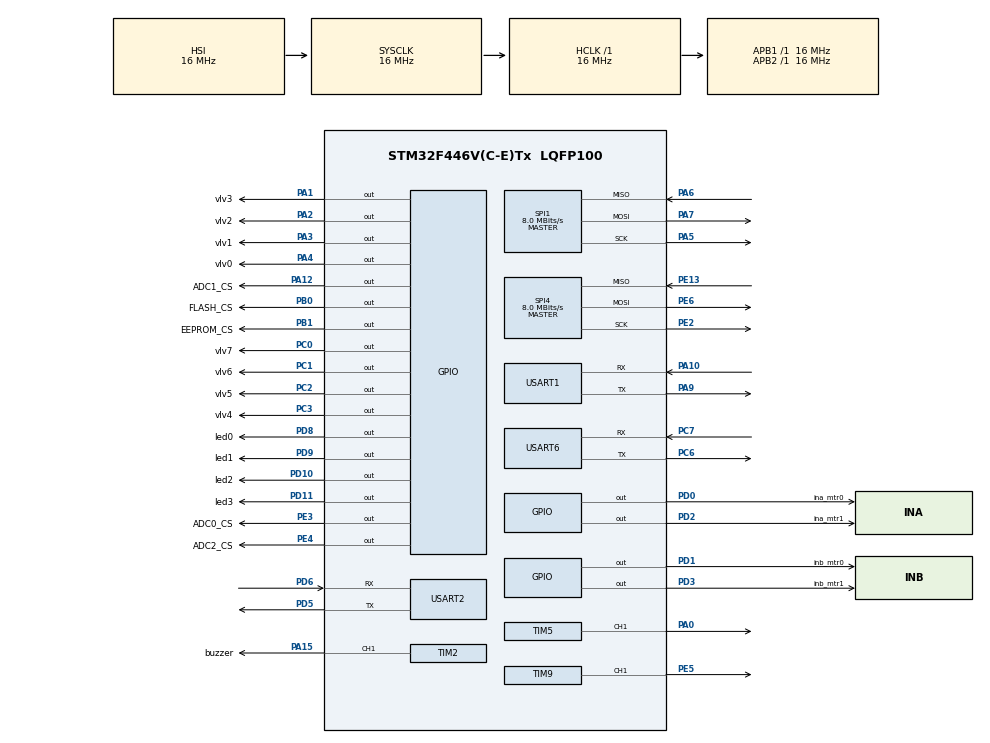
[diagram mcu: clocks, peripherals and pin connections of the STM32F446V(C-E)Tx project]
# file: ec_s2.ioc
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Mcu.Family=STM32F4
Mcu.Name=STM32F446V(C-E)Tx
Mcu.Package=LQFP100
NVIC.PriorityGroup=NVIC_PRIORITYGROUP_4
PA0-WKUP.Signal=S_TIM5_CH1
PA1.GPIO_Label=vlv3
PA1.Signal=GPIO_Output
PA10.Mode=Asynchronous
PA10.Signal=USART1_RX
PA12.GPIO_Label=ADC1_CS
PA12.Signal=GPIO_Output
PA13.Mode=Trace_Asynchronous_SW
PA13.Signal=SYS_JTMS-SWDIO
PA14.Mode=Trace_Asynchronous_SW
PA14.Signal=SYS_JTCK-SWCLK
PA15.GPIO_Label=buzzer
PA15.Signal=S_TIM2_CH1_ETR
PA2.GPIO_Label=vlv2
PA2.Signal=GPIO_Output
PA3.GPIO_Label=vlv1
PA3.Signal=GPIO_Output
PA4.GPIO_Label=vlv0
PA4.Signal=GPIO_Output
PA5.Mode=Full_Duplex_Master
PA5.Signal=SPI1_SCK
PA6.Mode=Full_Duplex_Master
PA6.Signal=SPI1_MISO
PA7.Mode=Full_Duplex_Master
PA7.Signal=SPI1_MOSI
PA9.Mode=Asynchronous
PA9.Signal=USART1_TX
PB0.GPIO_Label=FLASH_CS
PB0.Signal=GPIO_Output
PB1.GPIO_Label=EEPROM_CS
PB1.Signal=GPIO_Output
PB3.Mode=Trace_Asynchronous_SW
PB3.Signal=SYS_JTDO-SWO
PC0.GPIO_Label=vlv7
PC0.Signal=GPIO_Output
PC1.GPIO_Label=vlv6
PC1.Signal=GPIO_Output
PC2.GPIO_Label=vlv5
PC2.Signal=GPIO_Output
PC3.GPIO_Label=vlv4
PC3.Signal=GPIO_Output
PC6.Mode=Asynchronous
PC6.Signal=USART6_TX
PC7.Mode=Asynchronous
PC7.Signal=USART6_RX
PD0.GPIO_Label=ina_mtr0
PD0.Signal=GPIO_Output
PD1.GPIO_Label=inb_mtr0
PD1.Signal=GPIO_Output
PD10.GPIO_Label=led2
PD10.Signal=GPIO_Output
PD11.GPIO_Label=led3
PD11.Signal=GPIO_Output
PD2.GPIO_Label=ina_mtr1
PD2.Signal=GPIO_Output
PD3.GPIO_Label=inb_mtr1
PD3.Signal=GPIO_Output
PD5.Mode=Asynchronous
PD5.Signal=USART2_TX
PD6.Mode=Asynchronous
PD6.Signal=USART2_RX
PD8.GPIO_Label=led0
PD8.Signal=GPIO_Output
PD9.GPIO_Label=led1
PD9.Signal=GPIO_Output
PE13.Mode=Full_Duplex_Master
PE13.Signal=SPI4_MISO
PE2.Mode=Full_Duplex_Master
PE2.Signal=SPI4_SCK
PE3.GPIO_Label=ADC0_CS
PE3.Signal=GPIO_Output
PE4.GPIO_Label=ADC2_CS
PE4.Signal=GPIO_Output
PE5.Signal=S_TIM9_CH1
PE6.Mode=Full_Duplex_Master
PE6.Signal=SPI4_MOSI
ProjectManager.HeapSize=0x200
ProjectManager.StackSize=0x400
ProjectManager.TargetToolchain=TrueSTUDIO
RCC.AHBFreq_Value=16000000
RCC.APB1Freq_Value=16000000
RCC.APB1TimFreq_Value=16000000
RCC.APB2Freq_Value=16000000
RCC.APB2TimFreq_Value=16000000
RCC.CortexFreq_Value=16000000
RCC.HCLKFreq_Value=16000000
RCC.SYSCLKFreq_VALUE=16000000
RCC.USBFreq_Value=96000000
RCC.VCOOutputFreq_Value=192000000
SH.S_TIM2_CH1_ETR.0=TIM2_CH1,PWM Generation1 CH1
SH.S_TIM5_CH1.0=TIM5_CH1,PWM Generation1 CH1
SH.S_TIM9_CH1.0=TIM9_CH1,PWM Generation1 CH1
SPI1.BaudRatePrescaler=SPI_BAUDRATEPRESCALER_2
SPI1.CalculateBaudRate=8.0 MBits/s
SPI1.Direction=SPI_DIRECTION_2LINES
SPI1.Mode=SPI_MODE_MASTER
SPI1.VirtualType=VM_MASTER
SPI4.BaudRatePrescaler=SPI_BAUDRATEPRESCALER_2
SPI4.CalculateBaudRate=8.0 MBits/s
SPI4.Direction=SPI_DIRECTION_2LINES
SPI4.Mode=SPI_MODE_MASTER
SPI4.VirtualType=VM_MASTER
TIM2.Channel-PWM\ Generation1\ CH1=TIM_CHANNEL_1
TIM5.Channel-PWM\ Generation1\ CH1=TIM_CHANNEL_1
TIM9.Channel-PWM\ Generation1\ CH1=TIM_CHANNEL_1
USART1.VirtualMode=VM_ASYNC
USART2.VirtualMode=VM_ASYNC
USART6.VirtualMode=VM_ASYNC
board=ec_s2

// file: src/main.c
/**
  ******************************************************************************
  * @file           : main.c
  * @brief          : Main program body
  ******************************************************************************
  ** This notice applies to any and all portions of this file
  * that are not between comment pairs USER CODE BEGIN and
  * USER CODE END. Other portions of this file, whether
  * inserted by the user or by software development tools
  * are owned by their respective copyright owners.
  *
  * COPYRIGHT(c) 2018 STMicroelectronics
  *
  * Redistribution and use in source and binary forms, with or without modification,
  * are permitted provided that the following conditions are met:
  *   1. Redistributions of source code must retain the above copyright notice,
  *      this list of conditions and the following disclaimer.
  *   2. Redistributions in binary form must reproduce the above copyright notice,
  *      this list of conditions and the following disclaimer in the documentation
  *      and/or other materials provided with the distribution.
  *   3. Neither the name of STMicroelectronics nor the names of its contributors
  *      may be used to endorse or promote products derived from this software
  *      without specific prior written permission.
  *
  * THIS SOFTWARE IS PROVIDED BY THE COPYRIGHT HOLDERS AND CONTRIBUTORS "AS IS"
  * AND ANY EXPRESS OR IMPLIED WARRANTIES, INCLUDING, BUT NOT LIMITED TO, THE
  * IMPLIED WARRANTIES OF MERCHANTABILITY AND FITNESS FOR A PARTICULAR PURPOSE ARE
  * DISCLAIMED. IN NO EVENT SHALL THE COPYRIGHT HOLDER OR CONTRIBUTORS BE LIABLE
  * FOR ANY DIRECT, INDIRECT, INCIDENTAL, SPECIAL, EXEMPLARY, OR CONSEQUENTIAL
  * DAMAGES (INCLUDING, BUT NOT LIMITED TO, PROCUREMENT OF SUBSTITUTE GOODS OR
  * SERVICES; LOSS OF USE, DATA, OR PROFITS; OR BUSINESS INTERRUPTION) HOWEVER
  * CAUSED AND ON ANY THEORY OF LIABILITY, WHETHER IN CONTRACT, STRICT LIABILITY,
  * OR TORT (INCLUDING NEGLIGENCE OR OTHERWISE) ARISING IN ANY WAY OUT OF THE USE
  * OF THIS SOFTWARE, EVEN IF ADVISED OF THE POSSIBILITY OF SUCH DAMAGE.
  *
  ******************************************************************************
  */
#include "main.h"
#include "stm32f4xx_hal.h"

SPI_HandleTypeDef hspi1;
SPI_HandleTypeDef hspi4;

TIM_HandleTypeDef htim2;
TIM_HandleTypeDef htim5;
TIM_HandleTypeDef htim9;

UART_HandleTypeDef huart1;
UART_HandleTypeDef huart2;
UART_HandleTypeDef huart6;

/* USER CODE BEGIN PV */
/* Private variables ---------------------------------------------------------*/

/* USER CODE END PV */

void SystemClock_Config(void);
static void MX_GPIO_Init(void);
static void MX_SPI1_Init(void);
static void MX_SPI4_Init(void);
static void MX_TIM2_Init(void);
static void MX_TIM5_Init(void);
static void MX_TIM9_Init(void);
static void MX_USART1_UART_Init(void);
static void MX_USART2_UART_Init(void);
static void MX_USART6_UART_Init(void);

void HAL_TIM_MspPostInit(TIM_HandleTypeDef *htim);

/* USER CODE BEGIN PFP */
/* Private function prototypes -----------------------------------------------*/

/* USER CODE END PFP */

int main(void)
{

  /* MCU Configuration----------------------------------------------------------*/

  /* Reset of all peripherals, Initializes the Flash interface and the Systick. */
  HAL_Init();

  /* Configure the system clock */
  SystemClock_Config();

  /* Initialize all configured peripherals */
  MX_GPIO_Init();
  MX_SPI1_Init();
  MX_SPI4_Init();
  MX_TIM2_Init();
  MX_TIM5_Init();
  MX_TIM9_Init();
  MX_USART1_UART_Init();
  MX_USART2_UART_Init();
  MX_USART6_UART_Init();

  /* Infinite loop */
  /* USER CODE BEGIN WHILE */
  while (1)
  {

	  int d = 1000;

	  HAL_GPIO_WritePin(GPIOC, GPIO_PIN_0, GPIO_PIN_SET);
	  HAL_Delay(d);
	  HAL_GPIO_WritePin(GPIOC, GPIO_PIN_0, GPIO_PIN_RESET);
	  HAL_Delay(d);

  /* USER CODE END WHILE */

  }

}

void SystemClock_Config(void)
{

  RCC_OscInitTypeDef RCC_OscInitStruct;
  RCC_ClkInitTypeDef RCC_ClkInitStruct;

    /**Configure the main internal regulator output voltage
    */
  __HAL_RCC_PWR_CLK_ENABLE();

  __HAL_PWR_VOLTAGESCALING_CONFIG(PWR_REGULATOR_VOLTAGE_SCALE3);

    /**Initializes the CPU, AHB and APB busses clocks
    */
  RCC_OscInitStruct.OscillatorType = RCC_OSCILLATORTYPE_HSI;
  RCC_OscInitStruct.HSIState = RCC_HSI_ON;
  RCC_OscInitStruct.HSICalibrationValue = 16;
  RCC_OscInitStruct.PLL.PLLState = RCC_PLL_NONE;
  if (HAL_RCC_OscConfig(&RCC_OscInitStruct) != HAL_OK)
  {
    _Error_Handler(__FILE__, __LINE__);
  }

    /**Initializes the CPU, AHB and APB busses clocks
    */
  RCC_ClkInitStruct.ClockType = RCC_CLOCKTYPE_HCLK|RCC_CLOCKTYPE_SYSCLK
                              |RCC_CLOCKTYPE_PCLK1|RCC_CLOCKTYPE_PCLK2;
  RCC_ClkInitStruct.SYSCLKSource = RCC_SYSCLKSOURCE_HSI;
  RCC_ClkInitStruct.AHBCLKDivider = RCC_SYSCLK_DIV1;
  RCC_ClkInitStruct.APB1CLKDivider = RCC_HCLK_DIV1;
  RCC_ClkInitStruct.APB2CLKDivider = RCC_HCLK_DIV1;

  if (HAL_RCC_ClockConfig(&RCC_ClkInitStruct, FLASH_LATENCY_0) != HAL_OK)
  {
    _Error_Handler(__FILE__, __LINE__);
  }

    /**Configure the Systick interrupt time
    */
  HAL_SYSTICK_Config(HAL_RCC_GetHCLKFreq()/1000);

    /**Configure the Systick
    */
  HAL_SYSTICK_CLKSourceConfig(SYSTICK_CLKSOURCE_HCLK);

  /* SysTick_IRQn interrupt configuration */
  HAL_NVIC_SetPriority(SysTick_IRQn, 0, 0);
}

/* SPI1 init function */
static void MX_SPI1_Init(void)
{

  /* SPI1 parameter configuration*/
  hspi1.Instance = SPI1;
  hspi1.Init.Mode = SPI_MODE_MASTER;
  hspi1.Init.Direction = SPI_DIRECTION_2LINES;
  hspi1.Init.DataSize = SPI_DATASIZE_8BIT;
  hspi1.Init.CLKPolarity = SPI_POLARITY_LOW;
  hspi1.Init.CLKPhase = SPI_PHASE_1EDGE;
  hspi1.Init.NSS = SPI_NSS_SOFT;
  hspi1.Init.BaudRatePrescaler = SPI_BAUDRATEPRESCALER_2;
  hspi1.Init.FirstBit = SPI_FIRSTBIT_MSB;
  hspi1.Init.TIMode = SPI_TIMODE_DISABLE;
  hspi1.Init.CRCCalculation = SPI_CRCCALCULATION_DISABLE;
  hspi1.Init.CRCPolynomial = 10;
  if (HAL_SPI_Init(&hspi1) != HAL_OK)
  {
    _Error_Handler(__FILE__, __LINE__);
  }

}

/* SPI4 init function */
static void MX_SPI4_Init(void)
{

  /* SPI4 parameter configuration*/
  hspi4.Instance = SPI4;
  hspi4.Init.Mode = SPI_MODE_MASTER;
  hspi4.Init.Direction = SPI_DIRECTION_2LINES;
  hspi4.Init.DataSize = SPI_DATASIZE_8BIT;
  hspi4.Init.CLKPolarity = SPI_POLARITY_LOW;
  hspi4.Init.CLKPhase = SPI_PHASE_1EDGE;
  hspi4.Init.NSS = SPI_NSS_SOFT;
  hspi4.Init.BaudRatePrescaler = SPI_BAUDRATEPRESCALER_2;
  hspi4.Init.FirstBit = SPI_FIRSTBIT_MSB;
  hspi4.Init.TIMode = SPI_TIMODE_DISABLE;
  hspi4.Init.CRCCalculation = SPI_CRCCALCULATION_DISABLE;
  hspi4.Init.CRCPolynomial = 10;
  if (HAL_SPI_Init(&hspi4) != HAL_OK)
  {
    _Error_Handler(__FILE__, __LINE__);
  }

}

/* TIM2 init function */
static void MX_TIM2_Init(void)
{

  TIM_MasterConfigTypeDef sMasterConfig;
  TIM_OC_InitTypeDef sConfigOC;

  htim2.Instance = TIM2;
  htim2.Init.Prescaler = 0;
  htim2.Init.CounterMode = TIM_COUNTERMODE_UP;
  htim2.Init.Period = 0;
  htim2.Init.ClockDivision = TIM_CLOCKDIVISION_DIV1;
  if (HAL_TIM_PWM_Init(&htim2) != HAL_OK)
  {
    _Error_Handler(__FILE__, __LINE__);
  }

  sMasterConfig.MasterOutputTrigger = TIM_TRGO_RESET;
  sMasterConfig.MasterSlaveMode = TIM_MASTERSLAVEMODE_DISABLE;
  if (HAL_TIMEx_MasterConfigSynchronization(&htim2, &sMasterConfig) != HAL_OK)
  {
    _Error_Handler(__FILE__, __LINE__);
  }

  sConfigOC.OCMode = TIM_OCMODE_PWM1;
  sConfigOC.Pulse = 0;
  sConfigOC.OCPolarity = TIM_OCPOLARITY_HIGH;
  sConfigOC.OCFastMode = TIM_OCFAST_DISABLE;
  if (HAL_TIM_PWM_ConfigChannel(&htim2, &sConfigOC, TIM_CHANNEL_1) != HAL_OK)
  {
    _Error_Handler(__FILE__, __LINE__);
  }

  HAL_TIM_MspPostInit(&htim2);

}

/* TIM5 init function */
static void MX_TIM5_Init(void)
{

  TIM_MasterConfigTypeDef sMasterConfig;
  TIM_OC_InitTypeDef sConfigOC;

  htim5.Instance = TIM5;
  htim5.Init.Prescaler = 0;
  htim5.Init.CounterMode = TIM_COUNTERMODE_UP;
  htim5.Init.Period = 0;
  htim5.Init.ClockDivision = TIM_CLOCKDIVISION_DIV1;
  if (HAL_TIM_PWM_Init(&htim5) != HAL_OK)
  {
    _Error_Handler(__FILE__, __LINE__);
  }

  sMasterConfig.MasterOutputTrigger = TIM_TRGO_RESET;
  sMasterConfig.MasterSlaveMode = TIM_MASTERSLAVEMODE_DISABLE;
  if (HAL_TIMEx_MasterConfigSynchronization(&htim5, &sMasterConfig) != HAL_OK)
  {
    _Error_Handler(__FILE__, __LINE__);
  }

  sConfigOC.OCMode = TIM_OCMODE_PWM1;
  sConfigOC.Pulse = 0;
  sConfigOC.OCPolarity = TIM_OCPOLARITY_HIGH;
  sConfigOC.OCFastMode = TIM_OCFAST_DISABLE;
  if (HAL_TIM_PWM_ConfigChannel(&htim5, &sConfigOC, TIM_CHANNEL_1) != HAL_OK)
  {
    _Error_Handler(__FILE__, __LINE__);
  }

  HAL_TIM_MspPostInit(&htim5);

}

/* TIM9 init function */
static void MX_TIM9_Init(void)
{

  TIM_OC_InitTypeDef sConfigOC;

  htim9.Instance = TIM9;
  htim9.Init.Prescaler = 0;
  htim9.Init.CounterMode = TIM_COUNTERMODE_UP;
  htim9.Init.Period = 0;
  htim9.Init.ClockDivision = TIM_CLOCKDIVISION_DIV1;
  if (HAL_TIM_PWM_Init(&htim9) != HAL_OK)
  {
    _Error_Handler(__FILE__, __LINE__);
  }

  sConfigOC.OCMode = TIM_OCMODE_PWM1;
  sConfigOC.Pulse = 0;
  sConfigOC.OCPolarity = TIM_OCPOLARITY_HIGH;
  sConfigOC.OCFastMode = TIM_OCFAST_DISABLE;
  if (HAL_TIM_PWM_ConfigChannel(&htim9, &sConfigOC, TIM_CHANNEL_1) != HAL_OK)
  {
    _Error_Handler(__FILE__, __LINE__);
  }

  HAL_TIM_MspPostInit(&htim9);

}

/* USART1 init function */
static void MX_USART1_UART_Init(void)
{

  huart1.Instance = USART1;
  huart1.Init.BaudRate = 115200;
  huart1.Init.WordLength = UART_WORDLENGTH_8B;
  huart1.Init.StopBits = UART_STOPBITS_1;
  huart1.Init.Parity = UART_PARITY_NONE;
  huart1.Init.Mode = UART_MODE_TX_RX;
  huart1.Init.HwFlowCtl = UART_HWCONTROL_NONE;
  huart1.Init.OverSampling = UART_OVERSAMPLING_16;
  if (HAL_UART_Init(&huart1) != HAL_OK)
  {
    _Error_Handler(__FILE__, __LINE__);
  }

}

/* USART2 init function */
static void MX_USART2_UART_Init(void)
{

  huart2.Instance = USART2;
  huart2.Init.BaudRate = 115200;
  huart2.Init.WordLength = UART_WORDLENGTH_8B;
  huart2.Init.StopBits = UART_STOPBITS_1;
  huart2.Init.Parity = UART_PARITY_NONE;
  huart2.Init.Mode = UART_MODE_TX_RX;
  huart2.Init.HwFlowCtl = UART_HWCONTROL_NONE;
  huart2.Init.OverSampling = UART_OVERSAMPLING_16;
  if (HAL_UART_Init(&huart2) != HAL_OK)
  {
    _Error_Handler(__FILE__, __LINE__);
  }

}

/* USART6 init function */
static void MX_USART6_UART_Init(void)
{

  huart6.Instance = USART6;
  huart6.Init.BaudRate = 115200;
  huart6.Init.WordLength = UART_WORDLENGTH_8B;
  huart6.Init.StopBits = UART_STOPBITS_1;
  huart6.Init.Parity = UART_PARITY_NONE;
  huart6.Init.Mode = UART_MODE_TX_RX;
  huart6.Init.HwFlowCtl = UART_HWCONTROL_NONE;
  huart6.Init.OverSampling = UART_OVERSAMPLING_16;
  if (HAL_UART_Init(&huart6) != HAL_OK)
  {
    _Error_Handler(__FILE__, __LINE__);
  }

}

/** Configure pins as
        * Analog
        * Input
        * Output
        * EVENT_OUT
        * EXTI
*/
static void MX_GPIO_Init(void)
{

  GPIO_InitTypeDef GPIO_InitStruct;

  /* GPIO Ports Clock Enable */
  __HAL_RCC_GPIOE_CLK_ENABLE();
  __HAL_RCC_GPIOC_CLK_ENABLE();
  __HAL_RCC_GPIOA_CLK_ENABLE();
  __HAL_RCC_GPIOB_CLK_ENABLE();
  __HAL_RCC_GPIOD_CLK_ENABLE();

  /*Configure GPIO pin Output Level */
  HAL_GPIO_WritePin(GPIOE, ADC0_CS_Pin|ADC2_CS_Pin, GPIO_PIN_RESET);

  /*Configure GPIO pin Output Level */
  HAL_GPIO_WritePin(GPIOC, vlv7_Pin|vlv6_Pin|vlv5_Pin|vlv4_Pin, GPIO_PIN_RESET);

  /*Configure GPIO pin Output Level */
  HAL_GPIO_WritePin(GPIOA, vlv3_Pin|vlv2_Pin|vlv1_Pin|vlv0_Pin
                          |ADC1_CS_Pin, GPIO_PIN_RESET);

  /*Configure GPIO pin Output Level */
  HAL_GPIO_WritePin(GPIOB, FLASH_CS_Pin|EEPROM_CS_Pin, GPIO_PIN_RESET);

  /*Configure GPIO pin Output Level */
  HAL_GPIO_WritePin(GPIOD, led0_Pin|led1_Pin|led2_Pin|led3_Pin
                          |ina_mtr0_Pin|inb_mtr0_Pin|ina_mtr1_Pin|inb_mtr1_Pin, GPIO_PIN_RESET);

  /*Configure GPIO pins : ADC0_CS_Pin ADC2_CS_Pin */
  GPIO_InitStruct.Pin = ADC0_CS_Pin|ADC2_CS_Pin;
  GPIO_InitStruct.Mode = GPIO_MODE_OUTPUT_PP;
  GPIO_InitStruct.Pull = GPIO_NOPULL;
  GPIO_InitStruct.Speed = GPIO_SPEED_FREQ_LOW;
  HAL_GPIO_Init(GPIOE, &GPIO_InitStruct);

  /*Configure GPIO pins : vlv7_Pin vlv6_Pin vlv5_Pin vlv4_Pin */
  GPIO_InitStruct.Pin = vlv7_Pin|vlv6_Pin|vlv5_Pin|vlv4_Pin;
  GPIO_InitStruct.Mode = GPIO_MODE_OUTPUT_PP;
  GPIO_InitStruct.Pull = GPIO_NOPULL;
  GPIO_InitStruct.Speed = GPIO_SPEED_FREQ_LOW;
  HAL_GPIO_Init(GPIOC, &GPIO_InitStruct);

  /*Configure GPIO pins : vlv3_Pin vlv2_Pin vlv1_Pin vlv0_Pin
                           ADC1_CS_Pin */
  GPIO_InitStruct.Pin = vlv3_Pin|vlv2_Pin|vlv1_Pin|vlv0_Pin
                          |ADC1_CS_Pin;
  GPIO_InitStruct.Mode = GPIO_MODE_OUTPUT_PP;
  GPIO_InitStruct.Pull = GPIO_NOPULL;
  GPIO_InitStruct.Speed = GPIO_SPEED_FREQ_LOW;
  HAL_GPIO_Init(GPIOA, &GPIO_InitStruct);

  /*Configure GPIO pins : FLASH_CS_Pin EEPROM_CS_Pin */
  GPIO_InitStruct.Pin = FLASH_CS_Pin|EEPROM_CS_Pin;
  GPIO_InitStruct.Mode = GPIO_MODE_OUTPUT_PP;
  GPIO_InitStruct.Pull = GPIO_NOPULL;
  GPIO_InitStruct.Speed = GPIO_SPEED_FREQ_LOW;
  HAL_GPIO_Init(GPIOB, &GPIO_InitStruct);

  /*Configure GPIO pins : led0_Pin led1_Pin led2_Pin led3_Pin
                           ina_mtr0_Pin inb_mtr0_Pin ina_mtr1_Pin inb_mtr1_Pin */
  GPIO_InitStruct.Pin = led0_Pin|led1_Pin|led2_Pin|led3_Pin
                          |ina_mtr0_Pin|inb_mtr0_Pin|ina_mtr1_Pin|inb_mtr1_Pin;
  GPIO_InitStruct.Mode = GPIO_MODE_OUTPUT_PP;
  GPIO_InitStruct.Pull = GPIO_NOPULL;
  GPIO_InitStruct.Speed = GPIO_SPEED_FREQ_LOW;
  HAL_GPIO_Init(GPIOD, &GPIO_InitStruct);

}

void _Error_Handler(char *file, int line)
{
  while(1)
  {
  }
}

/************************ (C) COPYRIGHT STMicroelectronics *****END OF FILE****/
